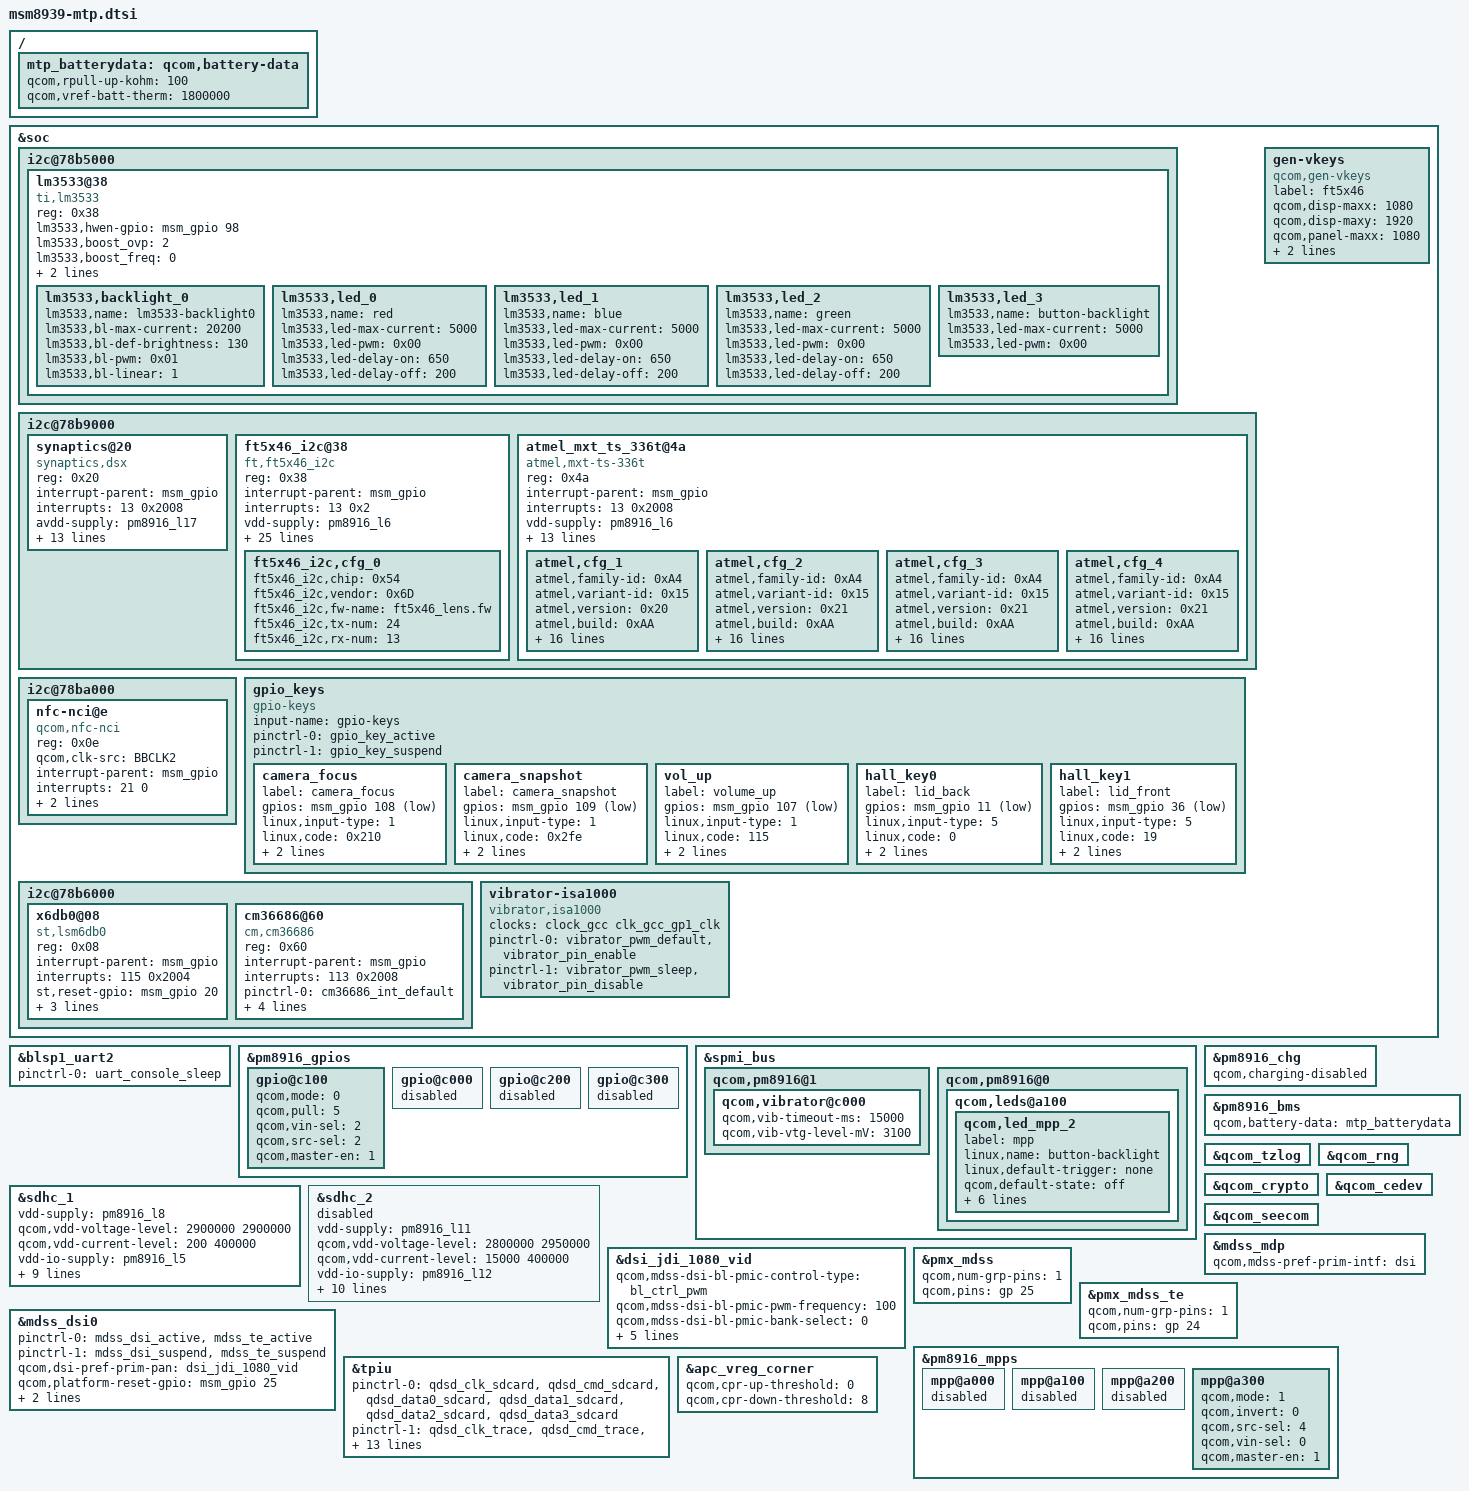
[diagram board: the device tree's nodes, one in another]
/* Copyright (c) 2014, The Linux Foundation. All rights reserved.
 * Copyright (C) 2015 XiaoMi, Inc.
 *
 * This program is free software; you can redistribute it and/or modify
 * it under the terms of the GNU General Public License version 2 and
 * only version 2 as published by the Free Software Foundation.
 *
 * This program is distributed in the hope that it will be useful,
 * but WITHOUT ANY WARRANTY; without even the implied warranty of
 * MERCHANTABILITY or FITNESS FOR A PARTICULAR PURPOSE.  See the
 * GNU General Public License for more details.
 */

#include "msm8939-pinctrl.dtsi"
#include "msm8939-camera-sensor-mtp.dtsi"

&soc {
	i2c@78b5000 { /* BLSP1 QUP1 */
		lm3533@38 {
						compatible = "ti,lm3533";
                        reg = <0x38>;
                        lm3533,hwen-gpio = <&msm_gpio 98 0x00>;
                        lm3533,boost_ovp = <2>;  /* 32v */
                        lm3533,boost_freq = <0>;  /* 500k */
                        lm3533,num_backlights = <1>;
                        lm3533,num_leds = <4>;
                        lm3533,backlight_0 {
						 		lm3533,name = "lm3533-backlight0";
                                lm3533,bl-max-current = <20200>;
                                lm3533,bl-def-brightness = <130>;
                                lm3533,bl-pwm = <0x01>;
                                lm3533,bl-linear = <1>;
                                };
                        lm3533,led_0 {
								lm3533,name = "red";
                                lm3533,led-max-current = <5000>;
                                lm3533,led-pwm = <0x00>;
                                lm3533,led-delay-on = <650>;
                                lm3533,led-delay-off = <200>;
                                };
                        lm3533,led_1 {
								lm3533,name = "blue";
                                lm3533,led-max-current = <5000>;
                                lm3533,led-pwm = <0x00>;
                                lm3533,led-delay-on = <650>;
                                lm3533,led-delay-off = <200>;
                                };
                        lm3533,led_2 {
								lm3533,name = "green";
                                lm3533,led-max-current = <5000>;
                                lm3533,led-pwm = <0x00>;
                                lm3533,led-delay-on = <650>;
                                lm3533,led-delay-off = <200>;
                                };
                        lm3533,led_3 {
                                lm3533,name = "button-backlight";
                                lm3533,led-max-current = <5000>;
                                lm3533,led-pwm = <0x00>;
                                };
                };
      };
	i2c@78b9000 { /* BLSP1 QUP5 */
		synaptics@20 {
			compatible = "synaptics,dsx";
			reg = <0x20>;
			interrupt-parent = <&msm_gpio>;
			interrupts = <13 0x2008>;
			avdd-supply = <&pm8916_l17>;
			vdd-supply = <&pm8916_l6>;
			/* pins used by touchscreen */
			pinctrl-names = "pmx_ts_active","pmx_ts_suspend","pmx_ts_suspend";
			pinctrl-0 = <&ts_int_active &ts_reset_active>;
			pinctrl-1 = <&ts_int_suspend &ts_reset_suspend>;
			pinctrl-2 = <&ts_release>;
			synaptics,irq-gpio = <&msm_gpio 13 0x2008>;
			synaptics,reset-gpio = <&msm_gpio 12 0x0>;
			synaptics,i2c-pull-up;
			synaptics,power-down;
			synaptics,disable-gpios;
			synaptics,display-coords = <0 0 1079 1919>;
			synaptics,panel-coords = <0 0 1079 2084>;
			/* Underlying clocks used by secure touch */
			clocks = <&clock_gcc clk_gcc_blsp1_ahb_clk>,
			 <&clock_gcc clk_gcc_blsp1_qup5_i2c_apps_clk>;
			clock-names = "iface_clk", "core_clk";
		};

		ft5x46_i2c@38 {
			compatible = "ft,ft5x46_i2c";
			reg = <0x38>;
			interrupt-parent = <&msm_gpio>;
			interrupts = <13 0x2>;
			vdd-supply = <&pm8916_l6>;
			/* pins used by touchscreen */
			pinctrl-names = "pmx_ts_active","pmx_ts_suspend";
			pinctrl-0 = <&ts_int_active &ts_reset_active &ts_pwr_active>;
			pinctrl-1 = <&ts_int_suspend &ts_reset_suspend &ts_pwr_suspend>;
			ft5x46_i2c,i2c-pull-up;
			ft5x46_i2c,irqflags = <0x2008>;
			ft5x46_i2c,x-max = <1080>;
			ft5x46_i2c,y-max = <1920>;
			ft5x46_i2c,z-max = <255>;
			ft5x46_i2c,w-max = <200>;
			ft5x46_i2c,reset-gpio = <&msm_gpio 12 0x00>;
			ft5x46_i2c,irq-gpio = <&msm_gpio 13 0x2>;
			ft5x46_i2c,power-ldo-gpio = <&msm_gpio 9 0x00>;
			ft5x46_i2c,power-ts-gpio = <&msm_gpio 78 0x00>;
			ft5x46_i2c,landing-jiffies = <1000>;
			ft5x46_i2c,landing-threshold = <16>;
			ft5x46_i2c,staying-threshold = <8>;
			ft5x46_i2c,raw-min = <7000>;
			ft5x46_i2c,raw-max = <10000>;
			ft5x46_i2c,fw-delay-55-ms = <2>;
			ft5x46_i2c,fw-delay-aa-ms = <2>;
			ft5x46_i2c,fw-upgrade-id1 = <0x54>;
			ft5x46_i2c,fw-upgrade-id2 = <0x2C>;
			ft5x46_i2c,fw-delay-readid-ms = <20>;
			ft5x46_i2c,firmware-array-size = <1>;
			ft5x46_i2c,cfg_0 {
				ft5x46_i2c,chip = <0x54>;
				ft5x46_i2c,vendor = <0x6D>;
				ft5x46_i2c,fw-name = "ft5x46_lens.fw";
				ft5x46_i2c,tx-num = <24>;
				ft5x46_i2c,rx-num = <13>;
			};
		};

		atmel_mxt_ts_336t@4a {
			compatible = "atmel,mxt-ts-336t";
			reg = <0x4a>;
			interrupt-parent = <&msm_gpio>;
			interrupts = <13 0x2008>;
			vdd-supply = <&pm8916_l6>;
			/* pins used by touchscreen */
			pinctrl-names = "pmx_ts_active","pmx_ts_suspend";
			pinctrl-0 = <&ts_int_active &ts_reset_active &ts_pwr_active>;
			pinctrl-1 = <&ts_int_suspend &ts_reset_suspend &ts_pwr_suspend>;
			atmel,reset-gpio = <&msm_gpio 12 0x00>;
			atmel,irq-gpio = <&msm_gpio 13 0x2008>;
			atmel,power-ldo-gpio = <&msm_gpio 9 0x00>;
			atmel,power-ts-gpio = <&msm_gpio 78 0x00>;
			atmel,mxt-fw-name = "mXT336T21AA.fw";
			atmel,config-array-size = <4>;
			atmel,default-config = <1>;
			atmel,irqflags = <0x2008>;
			atmel,gpio-mask = <0xC>;
			atmel,cfg_1 {
				atmel,family-id = <0xA4>;
				atmel,variant-id = <0x15>;
				atmel,version = <0x20>;
				atmel,build = <0xAA>;
				atmel,rev-id = <0x2>;
				atmel,mxt-cfg-name = "mxt_336t_wintek_config.fw";
				atmel,vendor-id = <0x0C>;
				atmel,panel-id = <0x33>; /* Wintek id = 0x33 */
				atmel,key-codes = <102 139 158>;
				atmel,key-num = <3>;
				atmel,selfintthr-stylus = <0>;
				atmel,t71-tchthr-pos = <22>;
				atmel,self-chgtime-min = <0>;
				atmel,self-chgtime-max = <0>;
				atmel,mult-intthr-sensitive = <12>;
				atmel,mult-intthr-not-sensitive = <17>;
				atmel,atchthr-sensitive = <6>;
				atmel,mult-tchthr-sensitive = <0>;
				atmel,mult-tchthr-not-sensitive = <0>;
				atmel,wake-up-self-adcx = <0>;
			};
			atmel,cfg_2 {
				atmel,family-id = <0xA4>;
				atmel,variant-id = <0x15>;
				atmel,version = <0x21>;
				atmel,build = <0xAA>;
				atmel,rev-id = <0x2>;
				atmel,mxt-cfg-name = "mxt_336t_biel_config.fw";
				atmel,vendor-id = <0x0C>;
				atmel,panel-id = <0x31>; /* Biel D1 id = 0x31 */
				atmel,key-codes = <102 139 158 116>;
				atmel,key-num = <4>;
				atmel,selfintthr-stylus = <0>;
				atmel,t71-tchthr-pos = <22>;
				atmel,self-chgtime-min = <0>;
				atmel,self-chgtime-max = <0>;
				atmel,mult-intthr-sensitive = <12>;
				atmel,mult-intthr-not-sensitive = <17>;
				atmel,atchthr-sensitive = <6>;
				atmel,mult-tchthr-sensitive = <0>;
				atmel,mult-tchthr-not-sensitive = <0>;
				atmel,wake-up-self-adcx = <16>;
			};
			atmel,cfg_3 {
				atmel,family-id = <0xA4>;
				atmel,variant-id = <0x15>;
				atmel,version = <0x21>;
				atmel,build = <0xAA>;
				atmel,rev-id = <0x2>;
				atmel,mxt-cfg-name = "mxt_336t_biel_config.fw";
				atmel,vendor-id = <0x0C>;
				atmel,panel-id = <0x35>; /* Biel TPB id = 0x35 */
				atmel,key-codes = <102 139 158 116>;
				atmel,key-num = <4>;
				atmel,selfintthr-stylus = <0>;
				atmel,t71-tchthr-pos = <22>;
				atmel,self-chgtime-min = <0>;
				atmel,self-chgtime-max = <0>;
				atmel,mult-intthr-sensitive = <12>;
				atmel,mult-intthr-not-sensitive = <17>;
				atmel,atchthr-sensitive = <6>;
				atmel,mult-tchthr-sensitive = <0>;
				atmel,mult-tchthr-not-sensitive = <0>;
				atmel,wake-up-self-adcx = <16>;
			};
			atmel,cfg_4 {
				atmel,family-id = <0xA4>;
				atmel,variant-id = <0x15>;
				atmel,version = <0x21>;
				atmel,build = <0xAA>;
				atmel,rev-id = <0x2>;
				atmel,mxt-cfg-name = "mxt_336t_tpk_config.fw";
				atmel,vendor-id = <0x0C>;
				atmel,panel-id = <0x36>; /* TPK id = 0x36 */
				atmel,key-codes = <102 139 158 116>;
				atmel,key-num = <4>;
				atmel,selfintthr-stylus = <0>;
				atmel,t71-tchthr-pos = <22>;
				atmel,self-chgtime-min = <0>;
				atmel,self-chgtime-max = <0>;
				atmel,mult-intthr-sensitive = <12>;
				atmel,mult-intthr-not-sensitive = <17>;
				atmel,atchthr-sensitive = <6>;
				atmel,mult-tchthr-sensitive = <0>;
				atmel,mult-tchthr-not-sensitive = <0>;
				atmel,wake-up-self-adcx = <16>;
			};
		};
	};

	gen-vkeys {
		compatible = "qcom,gen-vkeys";
		label = "ft5x46";
		qcom,disp-maxx = <1080>;
		qcom,disp-maxy = <1920>;
		qcom,panel-maxx = <1080>;
		qcom,panel-maxy = <2080>;
		qcom,key-codes = <139 102 158>;
	};

	i2c@78ba000 { /* BLSP1 QUP6 */
		nfc-nci@e {
			compatible = "qcom,nfc-nci";
			reg = <0x0e>;
			//qcom,irq-gpio = <&msm_gpio 21 0x00>;
			//qcom,dis-gpio = <&msm_gpio 20 0x00>;
			qcom,clk-src = "BBCLK2";
			interrupt-parent = <&msm_gpio>;
			interrupts = <21 0>;
			interrupt-names = "nfc_irq";
			//pinctrl-names = "nfc_active","nfc_suspend";
			//pinctrl-0 = <&nfc_int_active &nfc_disable_active>;
			//pinctrl-1 = <&nfc_int_suspend &nfc_disable_suspend>;
			qcom,clk-gpio = <&pm8916_gpios 2 0>;
			clocks = <&clock_rpm clk_bb_clk2_pin>;
			clock-names = "ref_clk";
		};
	};
	gpio_keys {
		compatible = "gpio-keys";
		input-name = "gpio-keys";
		pinctrl-names = "tlmm_gpio_key_active","tlmm_gpio_key_suspend";
		pinctrl-0 = <&gpio_key_active>;
		pinctrl-1 = <&gpio_key_suspend>;

		camera_focus {
			label = "camera_focus";
			gpios = <&msm_gpio 108 0x1>;
			linux,input-type = <1>;
			linux,code = <0x210>;
			gpio-key,wakeup;
			debounce-interval = <15>;
		};

		camera_snapshot {
			label = "camera_snapshot";
			gpios = <&msm_gpio 109 0x1>;
			linux,input-type = <1>;
			linux,code = <0x2fe>;
			gpio-key,wakeup;
			debounce-interval = <15>;
		};

		vol_up {
			label = "volume_up";
			gpios = <&msm_gpio 107 0x1>;
			linux,input-type = <1>;
			linux,code = <115>;
			gpio-key,wakeup;
			debounce-interval = <15>;
		};

		hall_key0 {
			label = "lid_back";
			gpios = <&msm_gpio 11 0x01>;
			linux,input-type = <5>;
			linux,code = <0>;
			gpio-key,wakeup;
			debounce-interval = <15>;
		};

		hall_key1 {
			label = "lid_front";
			gpios = <&msm_gpio 36 0x01>;
			linux,input-type = <5>;
			linux,code = <19>;
			gpio-key,wakeup;
			debounce-interval = <15>;
		};
	};

        i2c@78b6000 { /* BLSP1 QUP2 */
                x6db0@08 { /* Gyroscope and accelerometer sensor combo */
                        compatible = "st,lsm6db0";
                        reg = <0x08>;

			interrupt-parent = <&msm_gpio>;
			interrupts = <115 0x2004>;
                        st,reset-gpio = <&msm_gpio 20 0x00>;
                        st,wakeup-gpio = <&msm_gpio 102 0x00>;
                        vdd-supply = <&pm8916_l6>;
                        vmag-supply = <&pm8916_l17>;
                };
                cm36686@60 {
                        compatible = "cm,cm36686";
                        reg = <0x60>;

			interrupt-parent = <&msm_gpio>;
                        interrupts = <113 0x2008>;

			pinctrl-names = "default";
			pinctrl-0 = <&cm36686_int_default>;
                        als_trans_ratio = <16>;
                        prox_default_offset = <1000>;
                        prox_thres_near = <300>;
                        prox_thres_far = <200>;
                };
        };

	vibrator-isa1000 {
		compatible = "vibrator,isa1000";
		clocks = <&clock_gcc clk_gcc_gp1_clk>;
		clock-names = "vibrator_pwm";

		pinctrl-names = "pwm_default", "pwm_sleep";
		pinctrl-0 = <&vibrator_pwm_default &vibrator_pin_enable>;
		pinctrl-1 = <&vibrator_pwm_sleep &vibrator_pin_disable>;
	};
};

&blsp1_uart2 {
	status = "ok";
	pinctrl-names = "default";
	pinctrl-0 = <&uart_console_sleep>;
};

&pm8916_gpios {
	gpio@c100 { /* GPIO 2 */
		/* NFC_CLK_REQ */
		qcom,mode = <0>; /* QPNP_PIN_MODE_DIG_IN */
		qcom,pull = <5>; /* QPNP_PIN_PULL_NO */
		qcom,vin-sel = <2>; /* QPNP_PIN_VIN2 */
		qcom,src-sel = <2>; /* QPNP_PIN_SEL_FUNC_1 */
		qcom,master-en = <1>;
	};
};
&spmi_bus {
	qcom,pm8916@1 {
		qcom,vibrator@c000 {
			status = "okay";
			qcom,vib-timeout-ms = <15000>;
			qcom,vib-vtg-level-mV = <3100>;
		};
	};

	qcom,pm8916@0 {
		qcom,leds@a100 {
			status = "okay";
			qcom,led_mpp_2 {
				label = "mpp";
				linux,name = "button-backlight";
				linux,default-trigger = "none";
				qcom,default-state = "off";
				qcom,max-current = <40>;
				qcom,current-setting = <5>;
				qcom,id = <6>;
				qcom,mode = "manual";
				qcom,source-sel = <1>;
				qcom,mode-ctrl = <0x60>;
			};
		};
	};
};

&sdhc_1 {
	vdd-supply = <&pm8916_l8>;
	qcom,vdd-voltage-level = <2900000 2900000>;
	qcom,vdd-current-level = <200 400000>;

	vdd-io-supply = <&pm8916_l5>;
	qcom,vdd-io-always-on;
	qcom,vdd-io-lpm-sup;
	qcom,vdd-io-voltage-level = <1800000 1800000>;
	qcom,vdd-io-current-level = <200 60000>;

	pinctrl-names = "active", "sleep";
	pinctrl-0 = <&sdc1_clk_on &sdc1_cmd_on &sdc1_data_on>;
	pinctrl-1 = <&sdc1_clk_off &sdc1_cmd_off &sdc1_data_off>;

	qcom,nonremovable;

	status = "ok";
};

&sdhc_2 {
	vdd-supply = <&pm8916_l11>;
	qcom,vdd-voltage-level = <2800000 2950000>;
	qcom,vdd-current-level = <15000 400000>;

	vdd-io-supply = <&pm8916_l12>;
	qcom,vdd-io-voltage-level = <1800000 2950000>;
	qcom,vdd-io-current-level = <200 50000>;

	pinctrl-names = "active", "sleep";
	pinctrl-0 = <&sdc2_clk_on &sdc2_cmd_on &sdc2_data_on &sdc2_cd_on>;
	pinctrl-1 = <&sdc2_clk_off &sdc2_cmd_off &sdc2_data_off &sdc2_cd_off>;

	#address-cells = <0>;
	interrupt-parent = <&sdhc_2>;
	interrupts = <0 1 2>;
	#interrupt-cells = <1>;
	interrupt-map-mask = <0xffffffff>;
	interrupt-map = <0 &intc 0 125 0
			1 &intc 0 221 0>;
	interrupt-names = "hc_irq", "pwr_irq";

	status = "disable";
};

&pm8916_chg {
	status = "ok";
	qcom,charging-disabled;
};

/ {
	mtp_batterydata: qcom,battery-data {
		qcom,rpull-up-kohm = <100>;
		qcom,vref-batt-therm = <1800000>;

		#include "batterydata-palladium.dtsi"
	};
};

&pm8916_bms {
	status = "ok";
	qcom,battery-data = <&mtp_batterydata>;
};

&qcom_tzlog {
	status = "okay";
};

&qcom_rng {
	status = "okay";
};

&qcom_crypto {
	status = "okay";
};

&qcom_cedev {
	status = "okay";
};

&qcom_seecom {
	status = "okay";
};

#include "dsi-panel-jdi-1080p-video.dtsi"

&mdss_mdp {
	qcom,mdss-pref-prim-intf = "dsi";
};

&dsi_jdi_1080_vid {
	qcom,mdss-dsi-bl-pmic-control-type = "bl_ctrl_pwm";
	qcom,mdss-dsi-bl-pmic-pwm-frequency = <100>;
	qcom,mdss-dsi-bl-pmic-bank-select = <0>;
	qcom,mdss-dsi-pwm-gpio = <&pm8916_mpps 4 0>;
	qcom,cont-splash-enabled;
	qcom,mdss-dsi-pan-enable-dynamic-fps;
	qcom,mdss-dsi-pan-fps-update = "dfps_immediate_porch_mode";
};

&pmx_mdss {
	qcom,num-grp-pins = <1>;
	qcom,pins = <&gp 25>;
};

&pmx_mdss_te {
	qcom,num-grp-pins = <1>;
	qcom,pins = <&gp 24>;
};

&mdss_dsi0 {
	pinctrl-names = "mdss_default", "mdss_sleep";
	pinctrl-0 = <&mdss_dsi_active &mdss_te_active>;
	pinctrl-1 = <&mdss_dsi_suspend &mdss_te_suspend>;
	qcom,dsi-pref-prim-pan = <&dsi_jdi_1080_vid>;

	//qcom,platform-enable-gpio = <&msm_gpio 97 0>;
	qcom,platform-reset-gpio = <&msm_gpio 25 0>;
	//qcom,platform-bklight-en-gpio = <&msm_gpio 98 0>;
	qcom,platform-vsp-gpio = <&msm_gpio 116 0>;
	qcom,platform-vsn-gpio = <&msm_gpio 114 0>;
};

&pm8916_mpps {
	mpp@a000 { /* MPP 1 */
		/* VDD_PX */
		status = "disabled";
	};

	mpp@a100 { /* MPP 2 */
		/* HR LED */
		status = "disabled";
	};

	mpp@a200 { /* MPP 3 */
		/* VREF DAC */
		status = "disabled";
	};

	mpp@a300 { /* MPP 4 */
		/* Backlight PWM */
		qcom,mode = <1>;		/* Digital output */
		qcom,invert = <0>;		/* Disable invert */
		qcom,src-sel = <4>;		/* DTEST1 */
		qcom,vin-sel = <0>;		/* VPH_PWR */
		qcom,master-en = <1>;		/* Enable MPP */
	};
};

&pm8916_gpios {
	gpio@c000 { /* GPIO 1 */
		/* Battery UICC Alarm */
		status = "disabled";
	};

	gpio@c100 { /* GPIO 2 */
		/* NFC_CLK_REQ */
		qcom,mode = <0>; /* QPNP_PIN_MODE_DIG_IN */
		qcom,pull = <5>; /* QPNP_PIN_PULL_NO */
		qcom,vin-sel = <2>; /* QPNP_PIN_VIN2 */
		qcom,src-sel = <2>; /* QPNP_PIN_SEL_FUNC_1 */
		qcom,master-en = <1>;
	};

	gpio@c200 { /* GPIO 3 */
		/* External regulator control for WTR */
		status = "disabled";
	};

	gpio@c300 { /* GPIO 4 */
		/* External regulator control for APC */
		status = "disabled";
	};
};

/* CoreSight */
&tpiu {
	pinctrl-names = "sdcard", "trace", "swduart",
			"swdtrc", "jtag", "spmi";
	/* NIDnT */
	pinctrl-0 = <&qdsd_clk_sdcard &qdsd_cmd_sdcard
		     &qdsd_data0_sdcard &qdsd_data1_sdcard
		     &qdsd_data2_sdcard &qdsd_data3_sdcard>;
	pinctrl-1 = <&qdsd_clk_trace &qdsd_cmd_trace
		     &qdsd_data0_trace &qdsd_data1_trace
		     &qdsd_data2_trace &qdsd_data3_trace>;
	pinctrl-2 = <&qdsd_cmd_swduart &qdsd_data0_swduart
		     &qdsd_data1_swduart &qdsd_data2_swduart
		     &qdsd_data3_swduart>;
	pinctrl-3 = <&qdsd_clk_swdtrc &qdsd_cmd_swdtrc
		     &qdsd_data0_swdtrc &qdsd_data1_swdtrc
		     &qdsd_data2_swdtrc &qdsd_data3_swdtrc>;
	pinctrl-4 = <&qdsd_cmd_jtag &qdsd_data0_jtag
		     &qdsd_data1_jtag &qdsd_data2_jtag
		     &qdsd_data3_jtag>;
	pinctrl-5 = <&qdsd_clk_spmi &qdsd_cmd_spmi
		     &qdsd_data0_spmi &qdsd_data3_spmi>;
};

&apc_vreg_corner {
		qcom,cpr-up-threshold = <0>;
		qcom,cpr-down-threshold = <8>;
};
